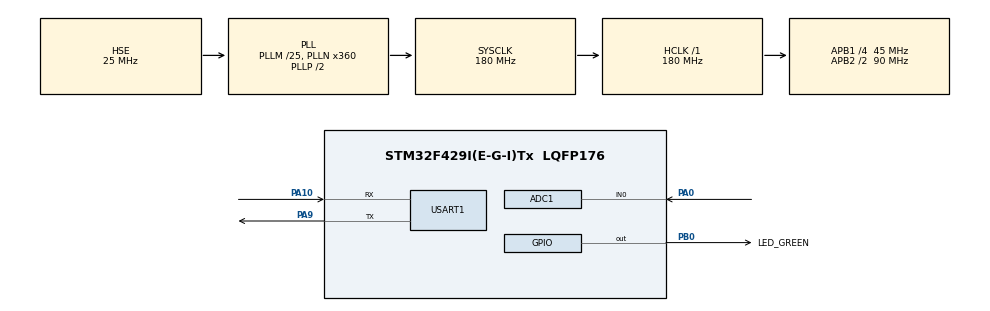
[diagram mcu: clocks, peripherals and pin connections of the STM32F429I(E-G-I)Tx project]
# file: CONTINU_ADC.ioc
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ADC1.Channel-0\#ChannelRegularConversion=ADC_CHANNEL_0
ADC1.ClockPrescaler=ADC_CLOCK_SYNC_PCLK_DIV2
ADC1.ContinuousConvMode=ENABLE
ADC1.DMAContinuousRequests=DISABLE
ADC1.DataAlign=ADC_DATAALIGN_RIGHT
ADC1.DiscontinuousConvMode=DISABLE
ADC1.EOCSelection=ADC_EOC_SINGLE_CONV
ADC1.EnableAnalogWatchDog=false
ADC1.ExternalTrigConvEdge=ADC_EXTERNALTRIGCONVEDGE_NONE
ADC1.InjNumberOfConversion=0
ADC1.NbrOfConversion=1
ADC1.NbrOfConversionFlag=1
ADC1.Rank-0\#ChannelRegularConversion=1
ADC1.Resolution=ADC_RESOLUTION_12B
ADC1.SamplingTime-0\#ChannelRegularConversion=ADC_SAMPLETIME_3CYCLES
ADC1.ScanConvMode=DISABLE
ADC1.master=1
Mcu.Family=STM32F4
Mcu.Name=STM32F429I(E-G-I)Tx
Mcu.Package=LQFP176
NVIC.PriorityGroup=NVIC_PRIORITYGROUP_2
NVIC.USART1_IRQn=true\:2\:0\:true\:false\:true
PA0/WKUP.GPIO_Mode=GPIO_MODE_ANALOG
PA0/WKUP.Signal=ADCx_IN0
PA10.Mode=Asynchronous
PA10.Signal=USART1_RX
PA9.Mode=Asynchronous
PA9.Signal=USART1_TX
PB0.GPIO_Label=LED_GREEN
PB0.GPIO_PuPd=GPIO_PULLUP
PB0.GPIO_Speed=GPIO_SPEED_FREQ_VERY_HIGH
PB0.PinState=GPIO_PIN_SET
PB0.Signal=GPIO_Output
PH0/OSC_IN.Mode=HSE-External-Oscillator
PH0/OSC_IN.Signal=RCC_OSC_IN
PH1/OSC_OUT.Mode=HSE-External-Oscillator
PH1/OSC_OUT.Signal=RCC_OSC_OUT
ProjectManager.HeapSize=0x200
ProjectManager.StackSize=0x400
ProjectManager.TargetToolchain=MDK-ARM V5
RCC.48MHZClocksFreq_Value=90000000
RCC.AHBFreq_Value=180000000
RCC.APB1CLKDivider=RCC_HCLK_DIV4
RCC.APB1Freq_Value=45000000
RCC.APB1TimFreq_Value=90000000
RCC.APB2CLKDivider=RCC_HCLK_DIV2
RCC.APB2Freq_Value=90000000
RCC.APB2TimFreq_Value=180000000
RCC.CortexFreq_Value=180000000
RCC.HCLKFreq_Value=180000000
RCC.HSE_VALUE=25000000
RCC.HSI_VALUE=16000000
RCC.LSE_VALUE=32768
RCC.PLLM=25
RCC.PLLN=360
RCC.PLLSourceVirtual=RCC_PLLSOURCE_HSE
RCC.SYSCLKFreq_VALUE=180000000
RCC.SYSCLKSource=RCC_SYSCLKSOURCE_PLLCLK
RCC.VCOOutputFreq_Value=360000000
SH.ADCx_IN0.0=ADC1_IN0,IN0
board=CONTINU_ADC

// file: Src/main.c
/**
  ******************************************************************************
  * File Name          : main.c
  * Description        : Main program body
  ******************************************************************************
  *
  * COPYRIGHT(c) 2020 STMicroelectronics
  *
  * Redistribution and use in source and binary forms, with or without modification,
  * are permitted provided that the following conditions are met:
  *   1. Redistributions of source code must retain the above copyright notice,
  *      this list of conditions and the following disclaimer.
  *   2. Redistributions in binary form must reproduce the above copyright notice,
  *      this list of conditions and the following disclaimer in the documentation
  *      and/or other materials provided with the distribution.
  *   3. Neither the name of STMicroelectronics nor the names of its contributors
  *      may be used to endorse or promote products derived from this software
  *      without specific prior written permission.
  *
  * THIS SOFTWARE IS PROVIDED BY THE COPYRIGHT HOLDERS AND CONTRIBUTORS "AS IS"
  * AND ANY EXPRESS OR IMPLIED WARRANTIES, INCLUDING, BUT NOT LIMITED TO, THE
  * IMPLIED WARRANTIES OF MERCHANTABILITY AND FITNESS FOR A PARTICULAR PURPOSE ARE
  * DISCLAIMED. IN NO EVENT SHALL THE COPYRIGHT HOLDER OR CONTRIBUTORS BE LIABLE
  * FOR ANY DIRECT, INDIRECT, INCIDENTAL, SPECIAL, EXEMPLARY, OR CONSEQUENTIAL
  * DAMAGES (INCLUDING, BUT NOT LIMITED TO, PROCUREMENT OF SUBSTITUTE GOODS OR
  * SERVICES; LOSS OF USE, DATA, OR PROFITS; OR BUSINESS INTERRUPTION) HOWEVER
  * CAUSED AND ON ANY THEORY OF LIABILITY, WHETHER IN CONTRACT, STRICT LIABILITY,
  * OR TORT (INCLUDING NEGLIGENCE OR OTHERWISE) ARISING IN ANY WAY OUT OF THE USE
  * OF THIS SOFTWARE, EVEN IF ADVISED OF THE POSSIBILITY OF SUCH DAMAGE.
  *
  ******************************************************************************
  */
#include "stm32f4xx_hal.h"
#include "adc.h"
#include "usart.h"
#include "gpio.h"

/* USER CODE BEGIN PV */
/* Private variables ---------------------------------------------------------*/

/* USER CODE END PV */

void SystemClock_Config(void);

/* USER CODE BEGIN PFP */
/* Private function prototypes -----------------------------------------------*/

/* USER CODE END PFP */

int main(void)
{

  /* USER CODE BEGIN 1 */
	float AD_Value;
  /* USER CODE END 1 */

  /* MCU Configuration----------------------------------------------------------*/

  /* Reset of all peripherals, Initializes the Flash interface and the Systick. */
  HAL_Init();

  /* Configure the system clock */
  SystemClock_Config();

  /* Initialize all configured peripherals */
  MX_GPIO_Init();
  MX_ADC1_Init();
  MX_USART1_UART_Init();

  /* Infinite loop */
  /* USER CODE BEGIN WHILE */
	//main
  while (1)
  {
  /* USER CODE END WHILE */
		AD_Value=GET_ADC_AVERAGE(hadc1,ADC_CHANNEL_0,20);
		AD_Value=AD_Value*3.3/4096;
		printf("\r\n %f \r\n",AD_Value);
  /* USER CODE BEGIN 3 */
		HAL_GPIO_WritePin(LED_GREEN_GPIO_Port,LED_GREEN_Pin,GPIO_PIN_RESET);
		HAL_Delay(300);
		HAL_GPIO_WritePin(LED_GREEN_GPIO_Port,LED_GREEN_Pin,GPIO_PIN_SET);
		HAL_Delay(300);
  /* USER CODE BEGIN 3 */
  }
  /* USER CODE END 3 */

}

/** System Clock Configuration
*/
void SystemClock_Config(void)
{

  RCC_OscInitTypeDef RCC_OscInitStruct;
  RCC_ClkInitTypeDef RCC_ClkInitStruct;

  __HAL_RCC_PWR_CLK_ENABLE();

  __HAL_PWR_VOLTAGESCALING_CONFIG(PWR_REGULATOR_VOLTAGE_SCALE1);

  RCC_OscInitStruct.OscillatorType = RCC_OSCILLATORTYPE_HSE;
  RCC_OscInitStruct.HSEState = RCC_HSE_ON;
  RCC_OscInitStruct.PLL.PLLState = RCC_PLL_ON;
  RCC_OscInitStruct.PLL.PLLSource = RCC_PLLSOURCE_HSE;
  RCC_OscInitStruct.PLL.PLLM = 25;
  RCC_OscInitStruct.PLL.PLLN = 360;
  RCC_OscInitStruct.PLL.PLLP = RCC_PLLP_DIV2;
  RCC_OscInitStruct.PLL.PLLQ = 4;
  HAL_RCC_OscConfig(&RCC_OscInitStruct);

  HAL_PWREx_EnableOverDrive();

  RCC_ClkInitStruct.ClockType = RCC_CLOCKTYPE_HCLK|RCC_CLOCKTYPE_SYSCLK
                              |RCC_CLOCKTYPE_PCLK1|RCC_CLOCKTYPE_PCLK2;
  RCC_ClkInitStruct.SYSCLKSource = RCC_SYSCLKSOURCE_PLLCLK;
  RCC_ClkInitStruct.AHBCLKDivider = RCC_SYSCLK_DIV1;
  RCC_ClkInitStruct.APB1CLKDivider = RCC_HCLK_DIV4;
  RCC_ClkInitStruct.APB2CLKDivider = RCC_HCLK_DIV2;
  HAL_RCC_ClockConfig(&RCC_ClkInitStruct, FLASH_LATENCY_5);

  HAL_SYSTICK_Config(HAL_RCC_GetHCLKFreq()/1000);

  HAL_SYSTICK_CLKSourceConfig(SYSTICK_CLKSOURCE_HCLK);

  /* SysTick_IRQn interrupt configuration */
  HAL_NVIC_SetPriority(SysTick_IRQn, 0, 0);
}

/************************ (C) COPYRIGHT STMicroelectronics *****END OF FILE****/
